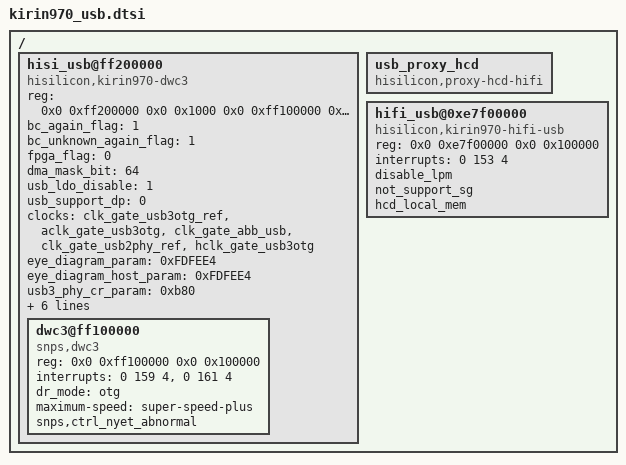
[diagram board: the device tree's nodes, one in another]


  /{
		hisi_usb@ff200000 {
			compatible = "hisilicon,kirin970-dwc3";
			reg = <0x0 0xff200000 0x0 0x1000 0x0 0xff100000 0x0 0x100000>;
			ranges;
			bc_again_flag = <1>;
			bc_unknown_again_flag = <1>;
			fpga_flag = <0>;
			dma_mask_bit = <64>;
			usb_ldo_disable = <1>;

			/* just cs-udp open */
			usb_support_dp = <0>;

			clocks = <&clk_gate_usb3otg_ref &aclk_gate_usb3otg &clk_gate_abb_usb &clk_gate_usb2phy_ref &hclk_gate_usb3otg>;
			clock-names = "clk_usb3phy_ref", "aclk_usb3otg", "clk_usb3_tcxo_en", "clk_usb2phy_ref", "hclk_usb3otg";

			eye_diagram_param = <0xFDFEE4>;
			eye_diagram_host_param = <0xFDFEE4>;
			usb3_phy_cr_param = <0xb80>;
			usb3_phy_host_cr_param = <0x980>;
			usb3_phy_tx_vboost_lvl = <0x5>;
			usb_aclk_freq = <238000000>;
			usb_support_check_voltage = <0x0>;
			set_hi_impedance = <0x0>;

			/* udp-overlay super-speed-plus */
			host-maximum-speed = "super-speed";

			dwc3@ff100000 {
				compatible = "snps,dwc3";
				reg = <0x0 0xff100000 0x0 0x100000>;
				interrupts = <0 159 4>, <0 161 4>;
				interrupt-names = "irq", "otg_irq";
				dr_mode = "otg";
				maximum-speed = "super-speed-plus";
				snps,ctrl_nyet_abnormal;
			};
		};

		usb_proxy_hcd {
			compatible = "hisilicon,proxy-hcd-hifi";
		};

		hifi_usb@0xe7f00000 {
			compatible = "hisilicon,kirin970-hifi-usb";
			reg = <0x0 0xe7f00000 0x0 0x100000>;
			interrupts = <0 153 4>;
			interrupt-names = "hifi_usb_irq";
			disable_lpm;
			not_support_sg;
			hcd_local_mem;
		};
  };
